VERSION ""

NS_ :

BS_:

BU_: DART MSB_F MSB_R SIB DRS

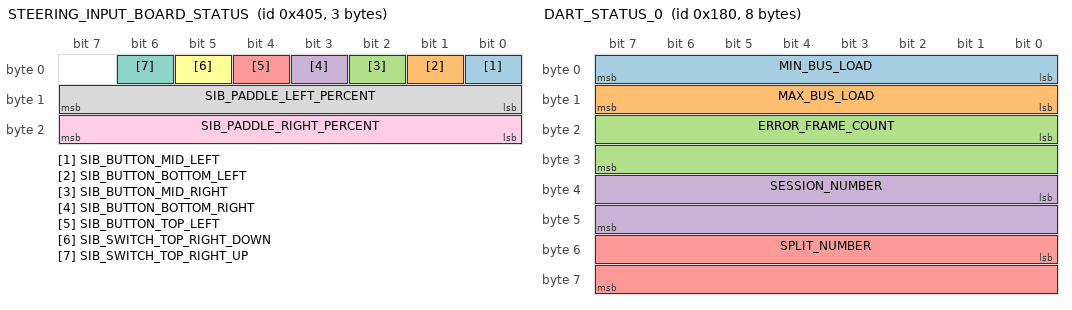
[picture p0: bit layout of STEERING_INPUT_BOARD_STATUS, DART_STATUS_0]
BO_ 1029 STEERING_INPUT_BOARD_STATUS: 3 SIB
 SG_ SIB_BUTTON_MID_LEFT : 0|1@1+ (1,0) [0|1] "Bool" Vector__XXX
 SG_ SIB_BUTTON_BOTTOM_LEFT : 1|1@1+ (1,0) [0|1] "Bool" Vector__XXX
 SG_ SIB_BUTTON_MID_RIGHT : 2|1@1+ (1,0) [0|1] "Bool" Vector__XXX
 SG_ SIB_BUTTON_BOTTOM_RIGHT : 3|1@1+ (1,0) [0|1] "Bool" Vector__XXX
 SG_ SIB_BUTTON_TOP_LEFT : 4|1@1+ (1,0) [0|1] "Bool" Vector__XXX
 SG_ SIB_SWITCH_TOP_RIGHT_DOWN : 5|1@1+ (1,0) [0|1] "Bool" Vector__XXX
 SG_ SIB_SWITCH_TOP_RIGHT_UP : 6|1@1+ (1,0) [0|1] "Bool" Vector__XXX
 SG_ SIB_PADDLE_LEFT_PERCENT : 8|8@1+ (0.392156862745,0) [0|100] "%" Vector__XXX
 SG_ SIB_PADDLE_RIGHT_PERCENT : 16|8@1+ (0.392156862745,0) [0|100] "%" Vector__XXX

BO_ 384 DART_STATUS_0: 8 DART
 SG_ MIN_BUS_LOAD : 0|8@1+ (0.6,0) [0|153] "%" Vector__XXX
 SG_ MAX_BUS_LOAD : 8|8@1+ (0.6,0) [0|153] "%" Vector__XXX
 SG_ ERROR_FRAME_COUNT : 16|16@1+ (1,0) [0|65535] "" Vector__XXX
 SG_ SESSION_NUMBER : 32|16@1+ (1,0) [0|65535] "" Vector__XXX
 SG_ SPLIT_NUMBER : 48|16@1+ (1,0) [0|65535] "" Vector__XXX

BO_ 1956 DRS_STATUS: 2 DRS
 SG_ DRS_EEPROM_STATUS : 0|2@1+ (1,0) [0|3] "Enum" Vector__XXX
 SG_ DRS_WING_OPEN : 0|2@1+ (1,0) [0|3] "Enum" Vector__XXX
 SG_ DRS_WING_ANGLE : 8|8@1+ (1,0) [0|3] "" Vector__XXX

BO_ 20 DRS_EEPROM_COMMAND: 6 Vector__XXX
 SG_ DRS_EEPROM_COMMAND_DATA_ADDRESS : 0|16@1+ (1,0) [0|1] "" Vector__XXX
 SG_ DRS_EEPROM_COMMAND_DATA : 16|32@1+ (1,0) [0|1] "" Vector__XXX

BO_ 21 DRS_EEPROM_RESPONSE: 6 Vector__XXX
 SG_ DRS_EEPROM_RESPONSE_DATA_ADDRESS : 0|16@1+ (1,0) [0|1] "" Vector__XXX
 SG_ DRS_EEPROM_RESPONSE_DATA : 16|32@1+ (1,0) [0|1] "" Vector__XXX

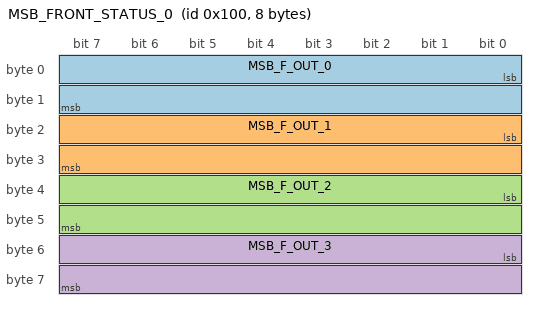
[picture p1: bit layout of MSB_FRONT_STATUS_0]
BO_ 256 MSB_FRONT_STATUS_0: 8 Vector__XXX
 SG_ MSB_F_OUT_0 : 0|16@1+ (0.000076295109,0) [0|5] "V" Vector__XXX
 SG_ MSB_F_OUT_1 : 16|16@1+ (0.000076295109,0) [0|5] "V" Vector__XXX
 SG_ MSB_F_OUT_2 : 32|16@1+ (0.000076295109,0) [0|5] "V" Vector__XXX
 SG_ MSB_F_OUT_3 : 48|16@1+ (0.000076295109,0) [0|5] "V" Vector__XXX

BA_DEF_  "BusType" STRING ;
BA_DEF_DEF_  "BusType" "CAN";
